# STM32H747_CM4 register map
File version: 1.8
CPU: CM4 r0p1, little endian, MPU, FPU, 4 interrupt priority bits
Registers are 32-bit, read-write, reset 0x0 unless marked. A register's access mark holds for its fields unless they carry their own. Offsets are from the block's base; [hi:lo] are bit positions; lines under a group give offsets from that group; {n}, {i} and the like mark numbered series.

## TIM6 — Basic timers
Base 0x40001000
Same registers: TIM7 0x40001400
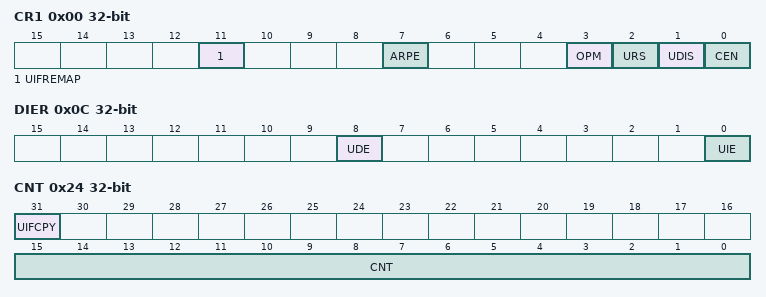
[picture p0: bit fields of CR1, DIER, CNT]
0x00 CR1 — control register 1
  [11] UIFREMAP — UIF status bit remapping
  [7] ARPE — Auto-reload preload enable
    0=Disabled (TIMx_APRR register is not buffered); 1=Enabled (TIMx_APRR register is buffered)
  [3] OPM — One-pulse mode
    0=Disabled (Counter is not stopped at update event); 1=Enabled (Counter stops counting at the next update event (clearing the CEN bit))
  [2] URS — Update request source
    0=AnyEvent (Any of counter overflow/underflow, setting UG, or update through slave mode, generates an update interrupt or DMA request); 1=CounterOnly (Only counter overflow/underflow generates an update interrupt or DMA request)
  [1] UDIS — Update disable
    0=Enabled (Update event enabled); 1=Disabled (Update event disabled)
  [0] CEN — Counter enable
    0=Disabled (Counter disabled); 1=Enabled (Counter enabled)
0x04 CR2 — control register 2
  [6:4] MMS — Master mode selection
    0=Reset (Use UG bit from TIMx_EGR register); 1=Enable (Use CNT bit from TIMx_CEN register); 2=Update (Use the update event)
0x0C DIER — DMA/Interrupt enable register
  [8] UDE — Update DMA request enable
    0=Disabled (Update DMA request disabled); 1=Enabled (Update DMA request enabled)
  [0] UIE — Update interrupt enable
    0=Disabled (Update interrupt disabled); 1=Enabled (Update interrupt enabled)
0x10 SR — status register
  [0] UIF write-0-clears — Update interrupt flag
    on read: 0=NoUpdateOccurred; 1=UpdatePending (Update interrupt pending) | on write: 0=Clear flag
0x14 EGR wo — event generation register
  [0] UG — Update generation
    1=Update (Re-initializes the timer counter and generates an update of the registers.)
0x24 CNT — counter
  [31] UIFCPY — UIF Copy
  [15:0] CNT — Low counter value
0x28 PSC — prescaler
  [15:0] PSC — Prescaler value
0x2C ARR — auto-reload register
  [15:0] ARR — Low Auto-reload value

## RAMECC1 — ECC controller is associated to each RAM area
Base 0x52009000
Same registers: RAMECC2 0x48023000
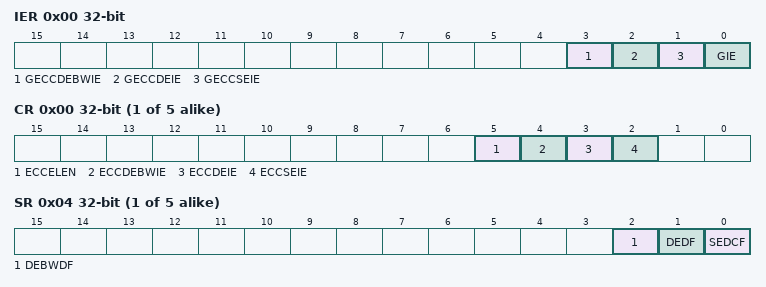
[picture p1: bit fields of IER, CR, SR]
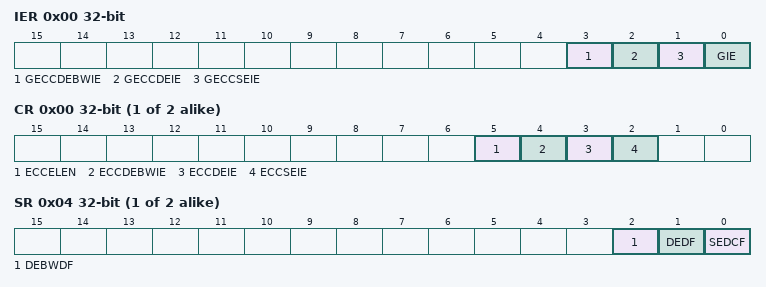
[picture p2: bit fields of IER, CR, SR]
0x00 IER — RAMECC interrupt enable register
  [3] GECCDEBWIE — Global ECC double error on byte write (BW) interrupt enable
  [2] GECCDEIE — Global ECC double error interrupt enable
  [1] GECCSEIE — Global ECC single error interrupt enable
  [0] GIE — Global interrupt enable
{0x0+0x20*i} M{i} (i=1..5) group — Cluster M{i}, containing M?CR, M?SR, M?FAR, M?FDRL, M?FDRH, M?FECR
  0x00 CR — RAMECC monitor x configuration register
    [5] ECCELEN — ECC error latching enable
    [4] ECCDEBWIE — ECC double error on byte write (BW) interrupt enable
    [3] ECCDEIE — ECC double error interrupt enable
    [2] ECCSEIE — ECC single error interrupt enable
  0x04 SR — RAMECC monitor x status register
    [2] DEBWDF — ECC double error on byte write (BW) detected flag
    [1] DEDF — ECC double error detected flag
    [0] SEDCF — ECC single error detected and corrected flag
  0x08 FAR ro — RAMECC monitor x failing address register
    [31:0] FADD — ECC error failing address
  0x0C FDRL ro — RAMECC monitor x failing data low register
    [31:0] FDATAL — Failing data low
  0x10 FDRH ro — RAMECC monitor x failing data high register
    [31:0] FDATAH — Failing data high (64-bit memory)
  0x14 FECR ro — RAMECC monitor x failing ECC error code register
    [31:0] FEC — Failing error code

## RAMECC3 — ECC controller is associated to each RAM area
Base 0x58027000
0x00 IER — RAMECC interrupt enable register
  [3] GECCDEBWIE — Global ECC double error on byte write (BW) interrupt enable
  [2] GECCDEIE — Global ECC double error interrupt enable
  [1] GECCSEIE — Global ECC single error interrupt enable
  [0] GIE — Global interrupt enable
{0x0+0x20*i} M{i} (i=1..2) group — Cluster M{i}, containing M?CR, M?SR, M?FAR, M?FDRL, M?FDRH, M?FECR
  0x00 CR — RAMECC monitor x configuration register
    [5] ECCELEN — ECC error latching enable
    [4] ECCDEBWIE — ECC double error on byte write (BW) interrupt enable
    [3] ECCDEIE — ECC double error interrupt enable
    [2] ECCSEIE — ECC single error interrupt enable
  0x04 SR — RAMECC monitor x status register
    [2] DEBWDF — ECC double error on byte write (BW) detected flag
    [1] DEDF — ECC double error detected flag
    [0] SEDCF — ECC single error detected and corrected flag
  0x08 FAR ro — RAMECC monitor x failing address register
    [31:0] FADD — ECC error failing address
  0x0C FDRL ro — RAMECC monitor x failing data low register
    [31:0] FDATAL — Failing data low
  0x10 FDRH ro — RAMECC monitor x failing data high register
    [31:0] FDATAH — Failing data high (64-bit memory)
  0x14 FECR ro — RAMECC monitor x failing ECC error code register
    [31:0] FEC — Failing error code

## ART — accelerator - control register (ART_CTR)
Base 0x40024400
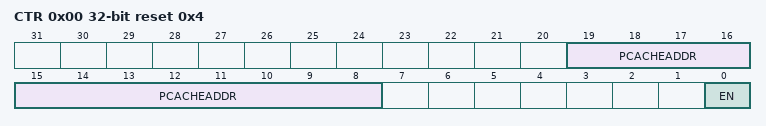
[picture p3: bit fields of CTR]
0x00 CTR reset 0x4 — control register
  [19:8] PCACHEADDR — Cacheable page index
  [0] EN — Cache enable
